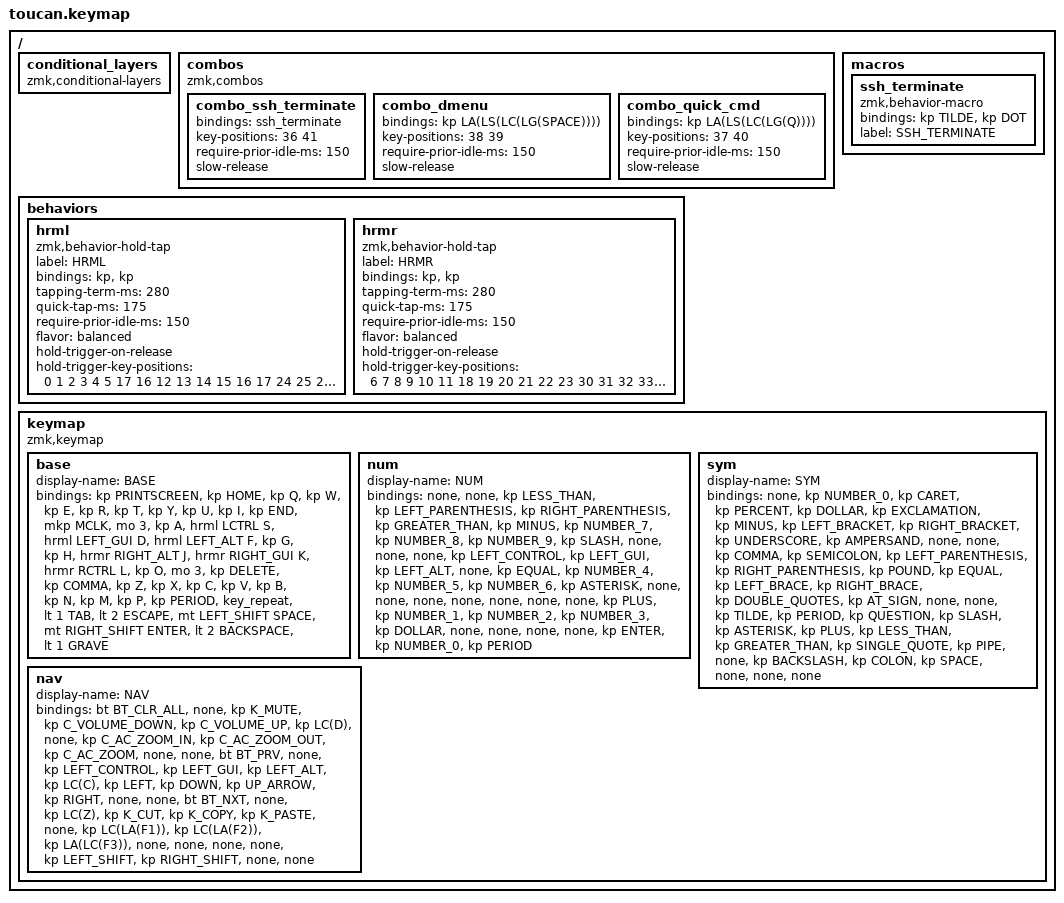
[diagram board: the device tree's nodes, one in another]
#include <behaviors.dtsi>
#include <dt-bindings/zmk/bt.h>
#include <dt-bindings/zmk/keys.h>
#include <dt-bindings/zmk/pointing.h>

/ {
    conditional_layers { compatible = "zmk,conditional-layers"; };

    combos {
        compatible = "zmk,combos";

        combo_ssh_terminate {
            bindings = <&ssh_terminate>;
            key-positions = <36 41>;
            require-prior-idle-ms = <150>;
            slow-release;
        };

        combo_dmenu {
            bindings = <&kp LA(LS(LC(LG(SPACE))))>;
            key-positions = <38 39>;
            require-prior-idle-ms = <150>;
            slow-release;
        };

        combo_quick_cmd {
            bindings = <&kp LA(LS(LC(LG(Q))))>;
            key-positions = <37 40>;
            require-prior-idle-ms = <150>;
            slow-release;
        };
    };

    behaviors {
        hrml: hrml {
            compatible = "zmk,behavior-hold-tap";
            label = "HRML";
            bindings = <&kp>, <&kp>;

            #binding-cells = <2>;
            tapping-term-ms = <280>;
            quick-tap-ms = <175>;
            require-prior-idle-ms = <150>;
            flavor = "balanced";
            hold-trigger-on-release;
            hold-trigger-key-positions = <0 1 2 3 4 5 17 16 12 13 14 15 16 17 24 25 26 27 28 29 36 37 38 39 41 40>;
        };

        hrmr: hrmr {
            compatible = "zmk,behavior-hold-tap";
            label = "HRMR";
            bindings = <&kp>, <&kp>;

            #binding-cells = <2>;
            tapping-term-ms = <280>;
            quick-tap-ms = <175>;
            require-prior-idle-ms = <150>;
            flavor = "balanced";
            hold-trigger-on-release;
            hold-trigger-key-positions = <6 7 8 9 10 11 18 19 20 21 22 23 30 31 32 33 34 35 40 41 39 36 37 38>;
        };
    };

    macros {
        ssh_terminate: ssh_terminate {
            compatible = "zmk,behavior-macro";
            #binding-cells = <0>;
            bindings = <&kp TILDE &kp DOT>;
            label = "SSH_TERMINATE";
        };
    };

    keymap {
        compatible = "zmk,keymap";

        base {
            display-name = "BASE";
            bindings = <
&kp PRINTSCREEN  &kp HOME  &kp Q  &kp W  &kp E  &kp R  &kp T  &kp Y  &kp U  &kp I  &kp END  &mkp MCLK  &mo 3  &kp A  &hrml LCTRL S  &hrml LEFT_GUI D  &hrml LEFT_ALT F  &kp G  &kp H  &hrmr RIGHT_ALT J  &hrmr RIGHT_GUI K  &hrmr RCTRL L  &kp O  &mo 3  &kp DELETE  &kp COMMA  &kp Z  &kp X  &kp C  &kp V  &kp B  &kp N  &kp M  &kp P  &kp PERIOD  &key_repeat  &lt 1 TAB  &lt 2 ESCAPE  &mt LEFT_SHIFT SPACE  &mt RIGHT_SHIFT ENTER  &lt 2 BACKSPACE  &lt 1 GRAVE
            >;
        };

        num {
            display-name = "NUM";
            bindings = <
&none  &none  &kp LESS_THAN  &kp LEFT_PARENTHESIS  &kp RIGHT_PARENTHESIS  &kp GREATER_THAN  &kp MINUS  &kp NUMBER_7  &kp NUMBER_8  &kp NUMBER_9  &kp SLASH  &none  &none  &none  &kp LEFT_CONTROL  &kp LEFT_GUI  &kp LEFT_ALT  &none  &kp EQUAL  &kp NUMBER_4  &kp NUMBER_5  &kp NUMBER_6  &kp ASTERISK  &none  &none  &none  &none  &none  &none  &none  &kp PLUS  &kp NUMBER_1  &kp NUMBER_2  &kp NUMBER_3  &kp DOLLAR  &none  &none  &none  &none  &kp ENTER  &kp NUMBER_0  &kp PERIOD
            >;
        };

        sym {
            display-name = "SYM";
            bindings = <
&none  &kp NUMBER_0  &kp CARET  &kp PERCENT  &kp DOLLAR  &kp EXCLAMATION  &kp MINUS  &kp LEFT_BRACKET  &kp RIGHT_BRACKET  &kp UNDERSCORE  &kp AMPERSAND  &none  &none  &kp COMMA  &kp SEMICOLON  &kp LEFT_PARENTHESIS  &kp RIGHT_PARENTHESIS  &kp POUND  &kp EQUAL  &kp LEFT_BRACE  &kp RIGHT_BRACE  &kp DOUBLE_QUOTES  &kp AT_SIGN  &none  &none  &kp TILDE  &kp PERIOD  &kp QUESTION  &kp SLASH  &kp ASTERISK  &kp PLUS  &kp LESS_THAN  &kp GREATER_THAN  &kp SINGLE_QUOTE  &kp PIPE  &none  &kp BACKSLASH  &kp COLON  &kp SPACE  &none  &none  &none
            >;
        };

        nav {
            display-name = "NAV";
            bindings = <
&bt BT_CLR_ALL  &none  &kp K_MUTE  &kp C_VOLUME_DOWN  &kp C_VOLUME_UP  &kp LC(D)  &none  &kp C_AC_ZOOM_IN  &kp C_AC_ZOOM_OUT  &kp C_AC_ZOOM  &none  &none  &bt BT_PRV  &none  &kp LEFT_CONTROL  &kp LEFT_GUI  &kp LEFT_ALT  &kp LC(C)  &kp LEFT  &kp DOWN  &kp UP_ARROW  &kp RIGHT  &none  &none  &bt BT_NXT  &none  &kp LC(Z)  &kp K_CUT  &kp K_COPY  &kp K_PASTE  &none  &kp LC(LA(F1))  &kp LC(LA(F2))  &kp LA(LC(F3))  &none  &none  &none  &none  &kp LEFT_SHIFT  &kp RIGHT_SHIFT  &none  &none
            >;
        };
    };
};
